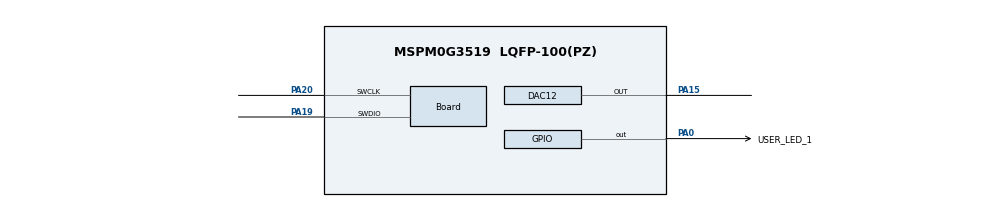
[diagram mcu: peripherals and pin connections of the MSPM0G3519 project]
//@cliArgs --device "MSPM0G351X" --package "LQFP-100(PZ)" --part "Default"
//@v2CliArgs --device "MSPM0G3519" --package "LQFP-100(PZ)"
// @cliArgs --board /ti/boards/LP_MSPM0G3519 --rtos nortos

/**
 * Import the modules used in this configuration.
 */
const COMP   = scripting.addModule("/ti/driverlib/COMP", {}, false);
const COMP1  = COMP.addInstance();
const DAC12  = scripting.addModule("/ti/driverlib/DAC12");
const GPIO   = scripting.addModule("/ti/driverlib/GPIO", {}, false);
const GPIO1  = GPIO.addInstance();
const GPIO2  = GPIO.addInstance();
const SYSCTL = scripting.addModule("/ti/driverlib/SYSCTL");
const TIMER  = scripting.addModule("/ti/driverlib/TIMER", {}, false);
const TIMER1 = TIMER.addInstance();

/**
 * Write custom configuration values to the imported modules.
 */
COMP1.$name              = "COMP_0";
COMP1.vSource            = "DL_COMP_REF_SOURCE_VDDA_DAC";
COMP1.controlSelect      = "DL_COMP_DAC_CONTROL_SW";
COMP1.peripheral.$assign = "COMP0";

const Board                       = scripting.addModule("/ti/driverlib/Board", {}, false);
Board.peripheral.$assign          = "DEBUGSS";
Board.peripheral.swclkPin.$assign = "PA20";
Board.peripheral.swdioPin.$assign = "PA19";

DAC12.dacOutputPinEn            = true;
DAC12.dacRes                    = "8BIT";
DAC12.peripheral.OutPin.$assign = "PA15";

GPIO1.$name                          = "GPIO_LEDS";
GPIO1.associatedPins[0].$name        = "USER_LED_1";
GPIO1.associatedPins[0].assignedPort = "PORTA";
GPIO1.associatedPins[0].assignedPin  = "0";
GPIO1.associatedPins[0].initialValue = "SET";
GPIO1.associatedPins[0].pin.$assign  = "PA0";

GPIO2.$name                              = "GPIO_SWITCHES";
GPIO2.associatedPins[0].assignedPort     = "PORTB";
GPIO2.associatedPins[0].$name            = "USER_SWITCH_1";
GPIO2.associatedPins[0].direction        = "INPUT";
GPIO2.associatedPins[0].internalResistor = "PULL_UP";
GPIO2.associatedPins[0].interruptEn      = true;
GPIO2.associatedPins[0].polarity         = "RISE_FALL";
GPIO2.associatedPins[0].assignedPin      = "3";

SYSCTL.MFCLKEn               = true;
SYSCTL.forceDefaultClkConfig = true;
SYSCTL.MFPCLKEn              = true;
SYSCTL.peripheral.$assign    = "SYSCTL";

TIMER1.$name              = "TIMER_0";
TIMER1.timerMode          = "PERIODIC";
TIMER1.timerClkDiv        = 8;
TIMER1.timerClkPrescale   = 128;
TIMER1.interrupts         = ["ZERO"];
TIMER1.timerPeriod        = "500ms";
TIMER1.peripheral.$assign = "TIMG0";

const ProjectConfig              = scripting.addModule("/ti/project_config/ProjectConfig", {}, false);
ProjectConfig.migrationCondition = true;
